# STM32H7x5 register map
File version: 1.1
CPU: CM7 r0p0, little endian, no MPU, no FPU, 3 interrupt priority bits
Registers are 32-bit, read-write, reset 0x0 unless marked. A register's access mark holds for its fields unless they carry their own. Offsets are from the block's base; [hi:lo] are bit positions; {n}, {i} and the like mark numbered series; 'fields as' and 'values as' point back to an identical list.

## COMP1
Base 0x58003800
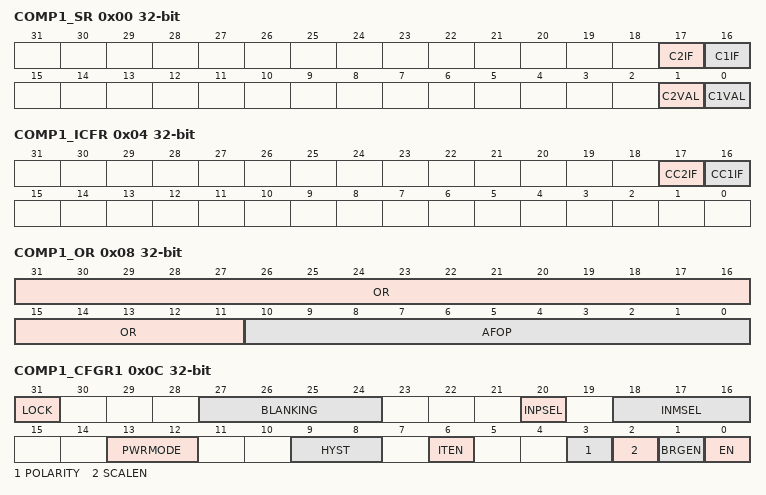
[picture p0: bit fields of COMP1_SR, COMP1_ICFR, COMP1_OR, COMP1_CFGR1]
0x00 COMP1_SR ro — Comparator status register
  [17] C2IF — COMP channel 2 Interrupt Flag
  [16] C1IF — COMP channel 1 Interrupt Flag
  [1] C2VAL — COMP channel 2 output status bit
  [0] C1VAL — COMP channel 1 output status bit
0x04 COMP1_ICFR wo — Comparator interrupt clear flag register
  [17] CC2IF — Clear COMP channel 2 Interrupt Flag
  [16] CC1IF — Clear COMP channel 1 Interrupt Flag
0x08 COMP1_OR — Comparator option register
  [31:11] OR — Option Register
  [10:0] AFOP — Selection of source for alternate function of output ports
0x0C COMP1_CFGR1 — Comparator configuration register 1
  [31] LOCK — Lock bit
  [27:24] BLANKING — COMP channel 1 blanking source selection bits
  [20] INPSEL — COMP channel 1 non-inverting input selection bit
  [18:16] INMSEL — COMP channel 1 inverting input selection field
  [13:12] PWRMODE — Power Mode of the COMP channel 1
  [9:8] HYST — COMP channel 1 hysteresis selection bits
  [6] ITEN — COMP channel 1 interrupt enable
  [3] POLARITY — COMP channel 1 polarity selection bit
  [2] SCALEN — Voltage scaler enable bit
  [1] BRGEN — Scaler bridge enable
  [0] EN — COMP channel 1 enable bit
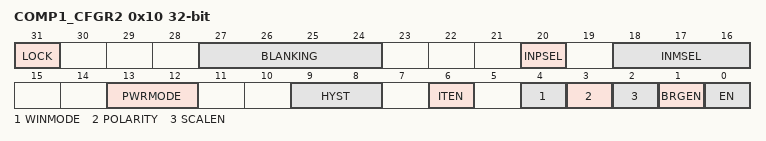
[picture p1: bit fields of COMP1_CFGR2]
0x10 COMP1_CFGR2 — Comparator configuration register 2
  [31] LOCK — Lock bit
  [27:24] BLANKING — COMP channel 1 blanking source selection bits
  [20] INPSEL — COMP channel 1 non-inverting input selection bit
  [18:16] INMSEL — COMP channel 1 inverting input selection field
  [13:12] PWRMODE — Power Mode of the COMP channel 1
  [9:8] HYST — COMP channel 1 hysteresis selection bits
  [6] ITEN — COMP channel 1 interrupt enable
  [4] WINMODE — Window comparator mode selection bit
  [3] POLARITY — COMP channel 1 polarity selection bit
  [2] SCALEN — Voltage scaler enable bit
  [1] BRGEN — Scaler bridge enable
  [0] EN — COMP channel 1 enable bit

## DMAMUX2 — DMAMUX
Base 0x58025800
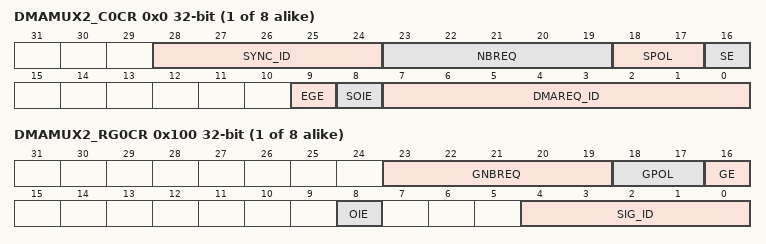
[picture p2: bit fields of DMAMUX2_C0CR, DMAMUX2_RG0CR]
{0x0+4i} DMAMUX2_C{i}CR (i=0..7) — DMAMux - DMA request line multiplexer channel x control register
  [28:24] SYNC_ID — Synchronization input selected
  [23:19] NBREQ — Number of DMA requests to forward Defines the number of DMA requests forwarded before output event is generated. In synchronous mode, it also defines the number of DMA requests to forward after a synchronization event, then stop forwarding. The actual number of DMA requests forwarded is NBREQ+1. Note: This field can only be written when both SE and EGE bits are reset.
  [18:17] SPOL — Synchronization event type selector Defines the synchronization event on the selected synchronization input:
  [16] SE — Synchronous operating mode enable/disable
  [9] EGE — Event generation enable/disable
  [8] SOIE — Interrupt enable at synchronization event overrun
  [7:0] DMAREQ_ID — Input DMA request line selected
0x80 DMAMUX2_CSR ro — DMAMUX request line multiplexer interrupt channel status register
  [15:0] SOF — Synchronization overrun event flag
0x84 DMAMUX2_CFR wo — DMAMUX request line multiplexer interrupt clear flag register
  [15:0] CSOF — Clear synchronization overrun event flag
{0x100+4i} DMAMUX2_RG{i}CR (i=0..7) — DMAMux - DMA request generator channel x control register
  [23:19] GNBREQ — Number of DMA requests to generate Defines the number of DMA requests generated after a trigger event, then stop generating. The actual number of generated DMA requests is GNBREQ+1. Note: This field can only be written when GE bit is reset.
  [18:17] GPOL — DMA request generator trigger event type selection Defines the trigger event on the selected DMA request trigger input
  [16] GE — DMA request generator channel enable/disable
  [8] OIE — Interrupt enable at trigger event overrun
  [4:0] SIG_ID — DMA request trigger input selected
0x140 DMAMUX2_RGSR ro — DMAMux - DMA request generator status register
  [7:0] OF — Trigger event overrun flag The flag is set when a trigger event occurs on DMA request generator channel x, while the DMA request generator counter value is lower than GNBREQ. The flag is cleared by writing 1 to the corresponding COFx bit in DMAMUX_RGCFR register.
0x144 DMAMUX2_RGCFR wo — DMAMux - DMA request generator clear flag register
  [7:0] COF — Clear trigger event overrun flag Upon setting, this bit clears the corresponding overrun flag OFx in the DMAMUX_RGCSR register.

## DMAMUX1 — DMAMUX
Base 0x40020800
Registers as DMAMUX2 (with DMAMUX2 read as DMAMUX1); these are added or differ:
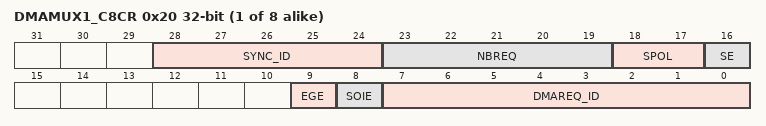
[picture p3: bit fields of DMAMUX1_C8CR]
{0x0+4i} DMAMUX1_C{i}CR (i=8..15) — DMAMux - DMA request line multiplexer channel x control register
  fields as DMAMUX2.DMAMUX2_C0CR
